# NAVSS0_NBSS_NB0_MEM_ATTR1_CFG register map
Vendor: Texas Instruments
Peripheral module from a debugger description file (folder am65x).
Registers are 32-bit, read-write, reset 0x50 unless marked. A register's access mark holds for its fields unless they carry their own. Offsets are as the file gives them; lines under a group give offsets from that group; [hi:lo] are bit positions; {n}, {i} and the like mark numbered series; 'fields as' and 'values as' point back to an identical list; <NAME> marks a mode.

## NAVSS0_NBSS_NB0_MEM_ATTR1_CFG
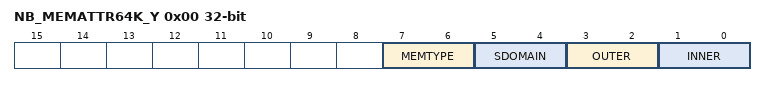
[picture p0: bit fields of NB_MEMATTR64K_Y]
0x00 NB_MEMATTR64K_Y — The Memory Attribute register contains the attributes for all the 64K mapped regions. Offset = 0h + (y * 4h); where y = 0h to 1FFFh
  [7:6] MEMTYPE — Defines the type of the memory
  [5:4] SDOMAIN — Defines the shareability domain of the memory
  [3:2] OUTER — Defines the outer allocatability of the memory
  [1:0] INNER — Defines the inner allocatability of the memory
